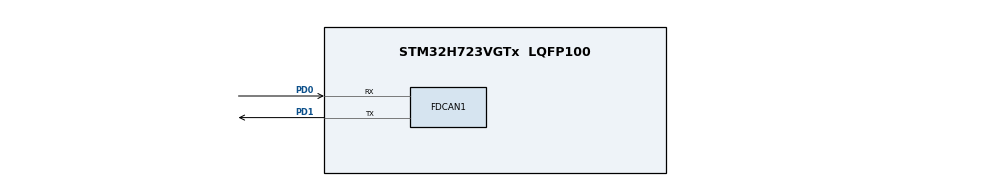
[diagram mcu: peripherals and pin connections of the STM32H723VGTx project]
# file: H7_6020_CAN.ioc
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CORTEX_M7.default_mode_Activation=1
FDCAN1.CalculateBaudRateNominal=1000000
FDCAN1.CalculateTimeBitNominal=1000
FDCAN1.CalculateTimeQuantumNominal=25.0
FDCAN1.DataPrescaler=3
FDCAN1.DataSyncJumpWidth=10
FDCAN1.DataTimeSeg1=29
FDCAN1.DataTimeSeg2=10
FDCAN1.NominalPrescaler=3
FDCAN1.NominalSyncJumpWidth=10
FDCAN1.NominalTimeSeg1=29
FDCAN1.NominalTimeSeg2=10
FDCAN1.RxFifo0ElmtsNbr=3
FDCAN1.StdFiltersNbr=1
Mcu.Family=STM32H7
Mcu.Name=STM32H723VGTx
Mcu.Package=LQFP100
NVIC.FDCAN1_IT0_IRQn=true\:0\:0\:false\:false\:true\:true\:true\:true
NVIC.FDCAN1_IT1_IRQn=true\:0\:0\:false\:false\:true\:true\:true\:true
NVIC.PriorityGroup=NVIC_PRIORITYGROUP_4
PA13(JTMS/SWDIO).Mode=Serial_Wire
PA13(JTMS/SWDIO).Signal=DEBUG_JTMS-SWDIO
PA14(JTCK/SWCLK).Mode=Serial_Wire
PA14(JTCK/SWCLK).Signal=DEBUG_JTCK-SWCLK
PD0.Mode=FDCAN_Activate
PD0.Signal=FDCAN1_RX
PD1.Mode=FDCAN_Activate
PD1.Signal=FDCAN1_TX
PH0-OSC_IN.Mode=HSE-External-Oscillator
PH0-OSC_IN.Signal=RCC_OSC_IN
PH1-OSC_OUT.Mode=HSE-External-Oscillator
PH1-OSC_OUT.Signal=RCC_OSC_OUT
ProjectManager.HeapSize=0x200
ProjectManager.StackSize=0x400
ProjectManager.TargetToolchain=STM32CubeIDE
RCC.ADCFreq_Value=100000000
RCC.APB1Freq_Value=120000000
RCC.APB2Freq_Value=120000000
RCC.APB3Freq_Value=120000000
RCC.APB4Freq_Value=120000000
RCC.CortexFreq_Value=480000000
RCC.D1PPRE=RCC_APB3_DIV2
RCC.D2PPRE1=RCC_APB1_DIV2
RCC.D2PPRE2=RCC_APB2_DIV2
RCC.D3PPRE=RCC_APB4_DIV2
RCC.DIVM1=2
RCC.DIVM2=24
RCC.DIVN1=40
RCC.DIVN2=200
RCC.DIVP1=1
RCC.DIVQ1=4
RCC.HCLKFreq_Value=240000000
RCC.HPRE=RCC_HCLK_DIV2
RCC.HSE_VALUE=24000000
RCC.PLL1_VCI_Range=RCC_PLL1VCIRANGE_3
RCC.PLLFRACN=0
RCC.PLLSourceVirtual=RCC_PLLSOURCE_HSE
RCC.SYSCLKFreq_VALUE=480000000
RCC.SYSCLKSource=RCC_SYSCLKSOURCE_PLLCLK
RCC.USBFreq_Value=120000000
VP_MEMORYMAP_VS_MEMORYMAP.Mode=CurAppReg
board=custom

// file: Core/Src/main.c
/* USER CODE BEGIN Header */
/**
  ******************************************************************************
  * @file           : main.c
  * @brief          : Main program body
  ******************************************************************************
  * @attention
  *
  * Copyright (c) 2026 STMicroelectronics.
  * All rights reserved.
  *
  * This software is licensed under terms that can be found in the LICENSE file
  * in the root directory of this software component.
  * If no LICENSE file comes with this software, it is provided AS-IS.
  *
  ******************************************************************************
  */
/* USER CODE END Header */
#include "main.h"
#include "fdcan.h"
#include "gpio.h"

/* USER CODE BEGIN Includes */
#include"string.h"
/* USER CODE END Includes */

/* USER CODE BEGIN PV */
struct data_6020
{
  uint16_t id;
  uint8_t rx_data[8];
  uint16_t angle;
  int16_t speed;
  int16_t current;
  int8_t temperature;

};
struct data_6020 rx_6020_feedback_t;
/* USER CODE END PV */

void SystemClock_Config(void);
static void MPU_Config(void);

/* USER CODE BEGIN 0 */
void Parse_6020(uint16_t id,uint8_t*data)
{
  rx_6020_feedback_t.id=id;
  memcpy(rx_6020_feedback_t.rx_data,data,8);

  rx_6020_feedback_t.angle=(rx_6020_feedback_t.rx_data[0]<<8|rx_6020_feedback_t.rx_data[1]);
  rx_6020_feedback_t.speed=(rx_6020_feedback_t.rx_data[2]<<8|rx_6020_feedback_t.rx_data[3]);
  rx_6020_feedback_t.current=(rx_6020_feedback_t.rx_data[4]<<8|rx_6020_feedback_t.rx_data[5]);
  rx_6020_feedback_t.temperature=(rx_6020_feedback_t.rx_data[6]);
}

void HAL_FDCAN_RxFifo0Callback(FDCAN_HandleTypeDef*hfdcan, uint32_t RxFifo0ITs)
{
	if((RxFifo0ITs&FDCAN_IT_RX_FIFO0_NEW_MESSAGE)!=RESET)
	{
		FDCAN_RxHeaderTypeDef RxHeader;
		uint8_t Rxdata[8];
			if(HAL_FDCAN_GetRxMessage(hfdcan,FDCAN_RX_FIFO0,&RxHeader,Rxdata)==HAL_OK)
			{
				if(
					RxHeader.IdType==FDCAN_STANDARD_ID&&
					RxHeader.DataLength==FDCAN_DLC_BYTES_8)
				{
					 Parse_6020(RxHeader.Identifier,Rxdata);
				}

			}
	}

}
/* USER CODE END 0 */

int main(void)
{

  /* MPU Configuration--------------------------------------------------------*/
  MPU_Config();

  /* MCU Configuration--------------------------------------------------------*/

  /* Reset of all peripherals, Initializes the Flash interface and the Systick. */
  HAL_Init();

  /* Configure the system clock */
  SystemClock_Config();

  /* Initialize all configured peripherals */
  MX_GPIO_Init();
  MX_FDCAN1_Init();
  /* USER CODE BEGIN 2 */
FDCAN_FilterTypeDef sFilterConfig;

  sFilterConfig.IdType=FDCAN_STANDARD_ID;
  sFilterConfig.FilterIndex=0;
  sFilterConfig.FilterType=FDCAN_FILTER_MASK;
  sFilterConfig.FilterConfig=FDCAN_FILTER_TO_RXFIFO0;
  sFilterConfig.FilterID1=0;
  sFilterConfig.FilterID2=0;

  if(HAL_FDCAN_ConfigFilter(&hfdcan1,&sFilterConfig)!=HAL_OK)
  {
	Error_Handler();
  }
  if(HAL_FDCAN_ConfigGlobalFilter(&hfdcan1,FDCAN_REJECT,FDCAN_REJECT,FDCAN_REJECT_REMOTE,FDCAN_REJECT_REMOTE)!=HAL_OK)
  {
	Error_Handler();
  }

  HAL_FDCAN_ActivateNotification(&hfdcan1,FDCAN_IT_RX_FIFO0_NEW_MESSAGE,0);
  HAL_FDCAN_Start(&hfdcan1);

  /* USER CODE END 2 */

  /* Infinite loop */
  while (1)
  {

  }
}

void SystemClock_Config(void)
{
  RCC_OscInitTypeDef RCC_OscInitStruct = {0};
  RCC_ClkInitTypeDef RCC_ClkInitStruct = {0};

  /** Supply configuration update enable
  */
  HAL_PWREx_ConfigSupply(PWR_LDO_SUPPLY);

  /** Configure the main internal regulator output voltage
  */
  __HAL_PWR_VOLTAGESCALING_CONFIG(PWR_REGULATOR_VOLTAGE_SCALE0);

  while(!__HAL_PWR_GET_FLAG(PWR_FLAG_VOSRDY)) {}

  /** Initializes the RCC Oscillators according to the specified parameters
  * in the RCC_OscInitTypeDef structure.
  */
  RCC_OscInitStruct.OscillatorType = RCC_OSCILLATORTYPE_HSE;
  RCC_OscInitStruct.HSEState = RCC_HSE_ON;
  RCC_OscInitStruct.PLL.PLLState = RCC_PLL_ON;
  RCC_OscInitStruct.PLL.PLLSource = RCC_PLLSOURCE_HSE;
  RCC_OscInitStruct.PLL.PLLM = 2;
  RCC_OscInitStruct.PLL.PLLN = 40;
  RCC_OscInitStruct.PLL.PLLP = 1;
  RCC_OscInitStruct.PLL.PLLQ = 4;
  RCC_OscInitStruct.PLL.PLLR = 2;
  RCC_OscInitStruct.PLL.PLLRGE = RCC_PLL1VCIRANGE_3;
  RCC_OscInitStruct.PLL.PLLVCOSEL = RCC_PLL1VCOWIDE;
  RCC_OscInitStruct.PLL.PLLFRACN = 0;
  if (HAL_RCC_OscConfig(&RCC_OscInitStruct) != HAL_OK)
  {
    Error_Handler();
  }

  /** Initializes the CPU, AHB and APB buses clocks
  */
  RCC_ClkInitStruct.ClockType = RCC_CLOCKTYPE_HCLK|RCC_CLOCKTYPE_SYSCLK
                              |RCC_CLOCKTYPE_PCLK1|RCC_CLOCKTYPE_PCLK2
                              |RCC_CLOCKTYPE_D3PCLK1|RCC_CLOCKTYPE_D1PCLK1;
  RCC_ClkInitStruct.SYSCLKSource = RCC_SYSCLKSOURCE_PLLCLK;
  RCC_ClkInitStruct.SYSCLKDivider = RCC_SYSCLK_DIV1;
  RCC_ClkInitStruct.AHBCLKDivider = RCC_HCLK_DIV2;
  RCC_ClkInitStruct.APB3CLKDivider = RCC_APB3_DIV2;
  RCC_ClkInitStruct.APB1CLKDivider = RCC_APB1_DIV2;
  RCC_ClkInitStruct.APB2CLKDivider = RCC_APB2_DIV2;
  RCC_ClkInitStruct.APB4CLKDivider = RCC_APB4_DIV2;

  if (HAL_RCC_ClockConfig(&RCC_ClkInitStruct, FLASH_LATENCY_3) != HAL_OK)
  {
    Error_Handler();
  }
}

 /* MPU Configuration */

void MPU_Config(void)
{
  MPU_Region_InitTypeDef MPU_InitStruct = {0};

  /* Disables the MPU */
  HAL_MPU_Disable();

  /** Initializes and configures the Region and the memory to be protected
  */
  MPU_InitStruct.Enable = MPU_REGION_ENABLE;
  MPU_InitStruct.Number = MPU_REGION_NUMBER0;
  MPU_InitStruct.BaseAddress = 0x0;
  MPU_InitStruct.Size = MPU_REGION_SIZE_4GB;
  MPU_InitStruct.SubRegionDisable = 0x87;
  MPU_InitStruct.TypeExtField = MPU_TEX_LEVEL0;
  MPU_InitStruct.AccessPermission = MPU_REGION_NO_ACCESS;
  MPU_InitStruct.DisableExec = MPU_INSTRUCTION_ACCESS_DISABLE;
  MPU_InitStruct.IsShareable = MPU_ACCESS_SHAREABLE;
  MPU_InitStruct.IsCacheable = MPU_ACCESS_NOT_CACHEABLE;
  MPU_InitStruct.IsBufferable = MPU_ACCESS_NOT_BUFFERABLE;

  HAL_MPU_ConfigRegion(&MPU_InitStruct);
  /* Enables the MPU */
  HAL_MPU_Enable(MPU_PRIVILEGED_DEFAULT);

}

void Error_Handler(void)
{
  __disable_irq();
  while (1)
  {
  }
}
